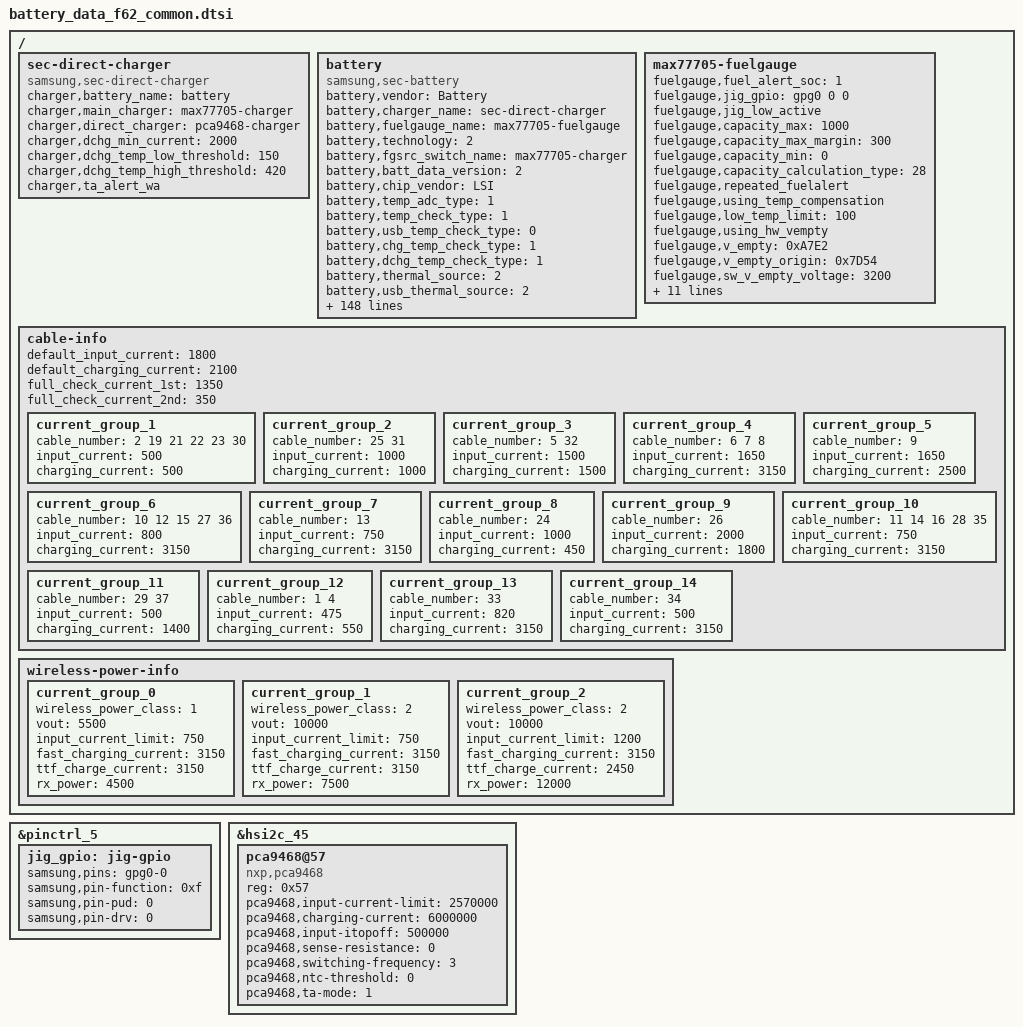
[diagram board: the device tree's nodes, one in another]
/*
 * SAMSUNG UNIVERSAL9820 board device tree source
 *
 * Copyright (c) 2018 Samsung Electronics Co., Ltd.
 *		http://www.samsung.com
 *
 * This program is free software; you can redistribute it and/or modify
 * it under the terms of the GNU General Public License version 2 as
 * published by the Free Software Foundation.
 */

&pinctrl_5 {
	jig_gpio: jig-gpio {
		samsung,pins = "gpg0-0";
		samsung,pin-function = <0xf>;
		samsung,pin-pud = <0>;
		samsung,pin-drv = <0>;
	};
};

/ {
	fragment@battery {
		target-path = "/";
		__overlay__ {
			sec-direct-charger {
				status = "okay";
				compatible = "samsung,sec-direct-charger";

				charger,battery_name = "battery";
				charger,main_charger = "max77705-charger";
				charger,direct_charger = "pca9468-charger";

				charger,dchg_min_current = <2000>;
				charger,dchg_temp_low_threshold = <150>;
				charger,dchg_temp_high_threshold = <420>;

				charger,ta_alert_wa;
			};

			battery {
				status = "okay";
				compatible = "samsung,sec-battery";

				pinctrl-names = "default";
				/* battery,irq_gpio = <&gpa1 6 0>; */

				battery,vendor = "Battery";
				battery,charger_name = "sec-direct-charger";
				battery,fuelgauge_name = "max77705-fuelgauge";
				battery,technology = <2>; /* POWER_SUPPLY_TECHNOLOGY_LION */
				battery,fgsrc_switch_name = "max77705-charger"; /* Fuelgauge voltage source */

				battery,batt_data_version = <2>;

				battery,chip_vendor = "LSI";
				battery,temp_adc_type = <1>; /* SEC_BATTERY_ADC_TYPE_AP */

				battery,temp_check_type = <1>; /* SEC_BATTERY_TEMP_CHECK_ADC */
				battery,usb_temp_check_type = <0>; /* SEC_BATTERY_TEMP_CHECK_NONE */
				battery,chg_temp_check_type = <1>; /* SEC_BATTERY_TEMP_CHECK_ADC */
				battery,dchg_temp_check_type = <1>; /* SEC_BATTERY_TEMP_CHECK_ADC */

				battery,thermal_source = <2>; /* SEC_BATTERY_THERMAL_SOURCE_ADC */
				battery,usb_thermal_source = <2>; /* SEC_BATTERY_THERMAL_SOURCE_ADC */
				battery,chg_thermal_source = <2>; /* SEC_BATTERY_THERMAL_SOURCE_ADC */
				battery,dchg_thermal_source = <3>; /* SEC_BATTERY_THERMAL_SOURCE_CHG_ADC */

				battery,polling_time = <10 30 30 30 3600>;

				battery,temp_table_adc = <308 360 419 494 583 683 804 955 1057 1256
					1430 1650 1875 2098 2305 2525 2736 2923 3060 3217 3347 3459 3551>;
				battery,temp_table_data = <900 850 800 750 700 650 600 550 500 450
					400 350 300 250 200 150 100 50 0 (-50) (-100) (-150) (-200)>;

				battery,usb_temp_table_adc = <293 343 409 479 562 657 770 899 1045 1212
					1395 1598 1815 2042 2275 2507 2733 2945 3139 3301 3442 3566 3677>;
				battery,usb_temp_table_data = <900 850 800 750 700 650 600 550 500 450
					400 350 300 250 200 150 100 50 0 (-50) (-100) (-150) (-200)>;

				battery,chg_temp_table_adc = <287 338 394 465 551 648 767 917 1017 1216
					1389 1611 1843 2074 2280 2519 2747 2950 3098 3271 3414 3527 3645>;
				battery,chg_temp_table_data = <900 850 800 750 700 650 600 550 500 450
					400 350 300 250 200 150 100 50 0 (-50) (-100) (-150) (-200)>;

				battery,dchg_temp_table_adc = <112608 134895 159528 188853 227562 269790 321402 387090 431664 519639
					598230 697935 803505 909075 1000569 1113177 1216401 1309068 1378275 1456866 1522554 1582377 1630470>;
				battery,dchg_temp_table_data = <900 850 800 750 700 650 600 550 500 450
					400 350 300 250 200 150 100 50 0 (-50) (-100) (-150) (-200)>;

				battery,cable_check_type = <4>; /* SEC_BATTERY_CABLE_CHECK_PSY */
				battery,cable_source_type = <1>; /* SEC_BATTERY_CABLE_SOURCE_EXTERNAL */
				battery,polling_type = <1>; /* SEC_BATTERY_MONITOR_ALARM */
				battery,monitor_initial_count = <0>;

				battery,battery_check_type = <0>; /* SEC_BATTERY_CHECK_NONE */
				battery,check_count = <0>;
				battery,check_adc_max = <1440>;
				battery,check_adc_min = <0>;

				battery,ovp_uvlo_check_type = <3>; /* SEC_BATTERY_OVP_UVLO_CHGPOLLING */

				battery,temp_check_count = <1>;
				battery,temp_highlimit_threshold_event = <700>;
				battery,temp_highlimit_recovery_event = <680>;
				battery,temp_high_threshold_event = <500>;
				battery,temp_high_recovery_event = <480>;
				battery,temp_low_threshold_event = <0>;
				battery,temp_low_recovery_event = <20>;
				battery,temp_highlimit_threshold_normal = <700>;
				battery,temp_highlimit_recovery_normal = <680>;
				battery,temp_high_threshold_normal = <500>;
				battery,temp_high_recovery_normal = <480>;
				battery,temp_low_threshold_normal = <0>;
				battery,temp_low_recovery_normal = <20>;
				battery,temp_highlimit_threshold_lpm = <700>;
				battery,temp_highlimit_recovery_lpm = <680>;
				battery,temp_high_threshold_lpm = <500>;
				battery,temp_high_recovery_lpm = <480>;
				battery,temp_low_threshold_lpm = <0>;
				battery,temp_low_recovery_lpm = <20>;

				battery,full_check_type = <2>; /* SEC_BATTERY_FULLCHARGED_FG_CURRENT */
				battery,full_check_type_2nd = <7>; /* SEC_BATTERY_FULLCHARGED_CHGPSY */
				battery,full_check_count = <1>;
				battery,chg_gpio_full_check = <0>;
				battery,chg_polarity_full_check = <1>;

				battery,chg_high_temp = <490>;
				battery,chg_high_temp_recovery = <470>;
				battery,dchg_high_temp = <650>;
				battery,dchg_high_temp_recovery = <630>;
				battery,chg_input_limit_current = <1000>;
				battery,chg_charging_limit_current = <1700>;
				battery,dchg_input_limit_current = <1000>;
				battery,dchg_charging_limit_current = <2000>;

				battery,ta_alert_wa;

				battery,mix_high_temp = <420>;
				battery,mix_high_chg_temp = <500>;
				battery,mix_high_temp_recovery = <390>;

				/* SEC_BATTERY_FULL_CONDITION_NOTIMEFULL | SEC_BATTERY_FULL_CONDITION_VCELL */
				battery,full_condition_type = <9>;
				battery,full_condition_soc = <93>;
				battery,full_condition_vcell = <4280>;

				battery,recharge_check_count = <1>;
				battery,recharge_condition_type = <4>; /* SEC_BATTERY_RECHARGE_CONDITION_VCELL */
				battery,recharge_condition_soc = <98>;
				battery,recharge_condition_vcell = <4310>;

				battery,charging_total_time = <14400>;
				battery,hv_charging_total_time = <10800>;
				battery,normal_charging_total_time = <18000>;
				battery,usb_charging_total_time = <36000>;
				battery,recharging_total_time = <5400>;
				battery,charging_reset_time = <0>;

				battery,chg_float_voltage = <4380>;
				battery,chg_ocp_current = <6200>;
				battery,chg_ocp_dtc = <100>;

				battery,swelling_high_temp_block = <420>;
				battery,swelling_high_temp_recov = <400>;
				battery,swelling_low_temp_block_1st = <150>;
				battery,swelling_low_temp_recov_1st = <170>;
				battery,swelling_low_temp_block_2nd = <50>;
				battery,swelling_low_temp_recov_2nd = <70>;

				battery,swelling_low_temp_current = <1750>;	/* 0.24C */
				battery,swelling_low_temp_current_2nd = <680>;	/* 0.1C */
				battery,swelling_low_temp_topoff = <350>;	/* 0.05C */
				battery,swelling_high_temp_current = <2650>;	/* 0.36C */
				battery,swelling_high_temp_topoff = <350>;	/* 0.05C */

				battery,swelling_drop_float_voltage = <4150>;
				battery,swelling_high_rechg_voltage = <4000>;
				battery,swelling_low_rechg_voltage = <4230>;
				battery,wa_float_voltage = <4050>;

				battery,siop_input_limit_current = <1200>;
				battery,siop_charging_limit_current = <1000>;
				battery,siop_hv_input_limit_current = <700>;
				battery,siop_hv_input_limit_current_2nd = <450>;
				battery,siop_hv_charging_limit_current = <1000>;
				battery,siop_apdo_input_limit_current = <1200>;
				battery,siop_apdo_charging_limit_current = <2000>;

				battery,ttf_hv_charge_current = <2740>;
				battery,ttf_dc25_charge_current = <3430>;

				battery,rp_current_rp1 = <500>;
				battery,rp_current_rp2 = <1500>;
				battery,rp_current_rp3 = <3000>;
				battery,rp_current_rdu_rp3 = <2100>;
				battery,rp_current_abnormal_rp3 = <1800>;

				battery,pd_charging_charge_power = <15000>;
				battery,max_charging_current = <3150>;
				battery,max_charging_charge_power = <25000>; /* 25W */
				battery,battery_full_capacity = <4400>;

				/* cycle, chg_float_voltage, recharge_condition_vcell, full_condition_vcell, full_condition_soc, step charging condition */
				battery,age_data = <0 4380 4310 4280 93 45
						300 4360 4290 4260 92 45
						400 4340 4270 4240 91 45
						700 4320 4250 4220 90 45
						1000 4270 4200 4170 89 45>;

				battery,health_condition = <
						/* CYCLE ASOC */
						900 75	/* GOOD */
						1200 65 /* NORMAL */
						1500 55 /* AGED */
						>;

				/* step charging option */
				battery,step_charging_type = <0>;
				battery,step_charging_charge_power = <12000>;
				battery,step_charging_condition = <45 100>;
				battery,step_charging_condition_curr = <3150 3150>;
				battery,step_charging_current = <3150 3150>;
				battery,step_charging_float_voltage = <4150 4380>;

				/* direct step charging option */
				battery,dc_step_chg_type = <0xE9>; /* origin(0x6B), soc option is temporary removed */
				battery,dc_step_chg_charge_power = <22000>;
				battery,dc_step_chg_step = <2>;
				battery,dc_step_chg_cond_vol = <4125 4380>; /* STEP_CHARGING_CONDITION_VOLTAGE */ 
				battery,dc_step_chg_cond_iin = <1950 0>; /* STEP_CHARGING_CONDITION_INPUT_CURRENT */
				battery,dc_step_chg_iin_check_cnt = <3>;
				battery,dc_step_chg_cond_soc = <25 100>; /* STEP_CHARGING_CONDITION_SOC */
				battery,dc_step_chg_val_vfloat = <4125 4380>; /* STEP_CHARGING_CONDITION_FLOAT_VOLTAGE */
				battery,dc_step_chg_val_iout = <5300 3900>;

				battery,pre_afc_input_current = <500>; /* mA */
				battery,prepare_ta_delay = <0>; /* msec */

				battery,max_input_voltage = <9000>; /* mV */
				battery,max_input_current = <3000>;  /* mA */

				battery,enable_sysovlo_irq;
				battery,enable_noise_wa;

				battery,standard_curr = <3450>;
				battery,expired_time = <12600>;
				battery,recharging_expired_time = <5400>;

				battery,cisd_max_voltage_thr = <4430>; /* battery ovp detection voltage */

				battery,cisd_alg_index = <8>;
				battery,ignore_cisd_index = <0 0>;
				battery,ignore_cisd_index_d = <0 80>; /* Do not use AFC_FAIL_PER_DAY to DROP_VALUE_PER_DAY */

				io-channels = <&exynos_adc 1>, <&exynos_adc 3>;
				io-channel-names = "adc-temp", "adc-chg-temp";
#io-channel-cells = <5>;
				io-channel-ranges;
			};

			max77705-fuelgauge {
				status = "okay";
				fuelgauge,fuel_alert_soc = <1>;
				fuelgauge,jig_gpio = <&gpg0 0 0>;
				fuelgauge,jig_low_active;
				fuelgauge,capacity_max = <1000>;
				fuelgauge,capacity_max_margin = <300>;
				fuelgauge,capacity_min = <0>;
				fuelgauge,capacity_calculation_type = <28>;
				fuelgauge,repeated_fuelalert;
				fuelgauge,using_temp_compensation;
				fuelgauge,low_temp_limit = <100>;
				fuelgauge,using_hw_vempty;
				fuelgauge,v_empty = <0xA7E2>; /* Empty: 3300mV, Recover: 3480mV */
				fuelgauge,v_empty_origin = <0x7D54>; /* Empty: 2500mV, Recover: 3360mV */
				fuelgauge,sw_v_empty_voltage = <3200>;
				fuelgauge,sw_v_empty_voltage_cisd = <3100>;
				fuelgauge,sw_v_empty_recover_voltage = <3480>;
				fuelgauge,fg_resistor = <2>;
				fuelgauge,capacity = <0x17DA>; /*capacity = fullcapnom = DesignCap*/
				fuelgauge,fg_reset_wa_data = <0x17DA 0x3200 0x05F6 0x0058 0x172F>; /* fullcapnom(=capacity), dPacc, dQacc,  rcomp0, tempco */
				/*fuelgauge,auto_discharge_en;*/
				fuelgauge,discharge_temp_threshold = <600>;
				fuelgauge,discharge_volt_threshold = <4200>;
				fuelgauge,ttf_capacity = <5800>;
				fuelgauge,cv_data = <
					2879	823	1853
					2740	828	1812
					2651	833	1771
					2603	837	1738
					2582	841	1699
					2508	846	1658
					2446	851	1617
					2400	854	1587
					2358	859	1546
					2312	863	1505
					2286	867	1466
					2199	870	1433
					1995	893	1198
					1792	902	1085
					1663	915	932
					1572	930	740
					1379	946	589
					1278	950	437
					1195	959	286
					1136	965	246
					1104	977	165
					1051	989	93
					843	1000	0
					>;
			};

			/* sec_battery_cable
			 *   0	UNKNOWN,
			 *   1	NONE,
			 *   2	PREPARE_TA,
			 *   3	TA,
			 *   4	USB,
			 *   5	USB_CDP,
			 *   6	9V_TA,
			 *   7	9V_ERR,
			 *   8	9V_UNKNOWN,
			 *   9	12V_TA,
			 *  10	WIRELESS,
			 *  11	HV_WIRELESS,
			 *  12	PMA_WIRELESS,
			 *  13	WIRELESS_PACK,
			 *  14	WIRELESS_HV_PACK,
			 *  15	WIRELESS_STAND,
			 *  16	WIRELESS_HV_STAND,
			 *  17	QC20,
			 *  18	QC30,
			 *  19	PDIC,
			 *  20	UARTOFF,
			 *  21	OTG,
			 *  22	LAN_HUB,
			 *  23	POWER_SHARING,
			 *  24	HMT_CONNECTED,
			 *  25	HMT_CHARGE,
			 *  26	HV_TA_CHG_LIMIT,
			 *  27	WIRELESS_VEHICLE,
			 *  28	WIRELESS_HV_VEHICLE,
			 *  29	PREPARE_WIRELESS_HV,
			 *  30	TIMEOUT,
			 *  31	SMART_OTG,
			 *  32	SMART_NOTG,
			 *  33	WIRELESS_TX,
			 *  34	HV_WIRELESS_20,
			 *  35	HV_WIRELESS_20_LIMIT,
			 *  36	WIRELESS_FAKE,
			 *  37  PREPARE_WIRELESS_20,
			 *  38	CABLE_PDIC_APDO,
			 *  39	CABLE_MAX,
			 */

			cable-info {
				default_input_current = <1800>;
				default_charging_current = <2100>;
				full_check_current_1st = <1350>;
				full_check_current_2nd = <350>;

				current_group_1 {
					cable_number = <2 19 21 22 23 30>;
					input_current = <500>;
					charging_current = <500>;
				};
				current_group_2 {
					cable_number = <25 31>;
					input_current = <1000>;
					charging_current = <1000>;
				};
				current_group_3 {
					cable_number = <5 32>;
					input_current = <1500>;
					charging_current = <1500>;
				};
				current_group_4 {
					cable_number = <6 7 8>;
					input_current = <1650>;
					charging_current = <3150>;
				};
				current_group_5 {
					cable_number = <9>;
					input_current = <1650>;
					charging_current = <2500>;
				};
				current_group_6 {
					cable_number = <10 12 15 27 36>;
					input_current = <800>;
					charging_current = <3150>;
				};
				current_group_7 {
					cable_number = <13>;
					input_current = <750>;
					charging_current = <3150>;
				};
				current_group_8 {
					cable_number = <24>;
					input_current = <1000>;
					charging_current = <450>;
				};
				current_group_9 {
					cable_number = <26>;
					input_current = <2000>;
					charging_current = <1800>;
				};
				current_group_10 {
					cable_number = <11 14 16 28 35>;
					input_current = <750>;
					charging_current = <3150>;
				};
				current_group_11 {
					cable_number = <29 37>;
					input_current = <500>;
					charging_current = <1400>;
				};
				current_group_12 {
					cable_number = <1 4>;
					input_current = <475>;
					charging_current = <550>;
				};
				current_group_13 {
					cable_number = <33>;
					input_current = <820>;
					charging_current = <3150>;
				};
				current_group_14 {
					cable_number = <34>;
					input_current = <500>;
					charging_current = <3150>;
				};
			};
			wireless-power-info {
				current_group_0 {
					wireless_power_class = <1>;
					vout = <5500>;
					input_current_limit = <750>;
					fast_charging_current = <3150>;
					ttf_charge_current = <3150>;
					rx_power = <4500>;
				};
				current_group_1 {
					wireless_power_class = <2>;
					vout = <10000>;
					input_current_limit = <750>;
					fast_charging_current = <3150>;
					ttf_charge_current = <3150>;
					rx_power = <7500>;
				};
				current_group_2 {
					wireless_power_class = <2>;
					vout = <10000>;
					input_current_limit = <1200>;
					fast_charging_current = <3150>;
					ttf_charge_current = <2450>;
					rx_power = <12000>;
				};
			};
		}; /* end of __overlay__ */
	}; /* end of fragment */
};

&hsi2c_45 {
	status = "okay";

	pca9468@57 {
		compatible = "nxp,pca9468";
		reg = <0x57>;
		pinctrl-names = "default";

		pca9468,input-current-limit = <2570000>; /* 2.57A */
		pca9468,charging-current = <6000000>; /* 6A */
		pca9468,input-itopoff = <500000>; /* 500mA */
		pca9468,sense-resistance = <0>; /* 5mOhm */
		pca9468,switching-frequency = <3>; /* 980KHz */
		pca9468,ntc-threshold = <0>; /* disable */
		pca9468,ta-mode = <1>; /* 2:1 charging mode */
	};
};
